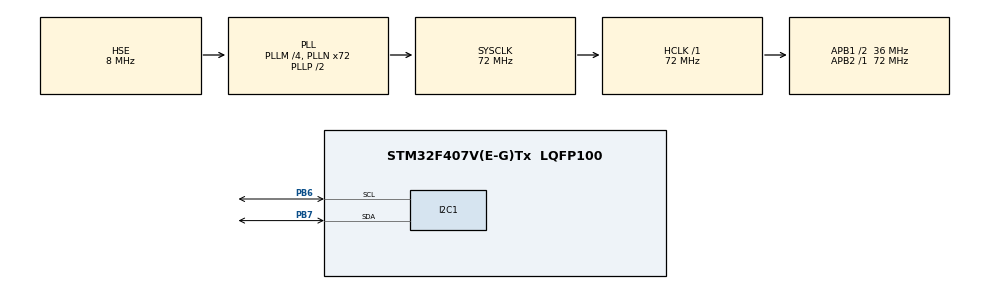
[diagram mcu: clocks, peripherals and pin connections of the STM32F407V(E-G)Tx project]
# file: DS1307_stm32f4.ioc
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Mcu.Family=STM32F4
Mcu.Name=STM32F407V(E-G)Tx
Mcu.Package=LQFP100
NVIC.PriorityGroup=NVIC_PRIORITYGROUP_4
PA13.Mode=Serial_Wire
PA13.Signal=SYS_JTMS-SWDIO
PA14.Mode=Serial_Wire
PA14.Signal=SYS_JTCK-SWCLK
PB6.Mode=I2C
PB6.Signal=I2C1_SCL
PB7.Mode=I2C
PB7.Signal=I2C1_SDA
PH0-OSC_IN.Mode=HSE-External-Oscillator
PH0-OSC_IN.Signal=RCC_OSC_IN
PH1-OSC_OUT.Mode=HSE-External-Oscillator
PH1-OSC_OUT.Signal=RCC_OSC_OUT
ProjectManager.HeapSize=0x200
ProjectManager.StackSize=0x400
ProjectManager.TargetToolchain=STM32CubeIDE
RCC.48MHZClocksFreq_Value=36000000
RCC.AHBFreq_Value=72000000
RCC.APB1CLKDivider=RCC_HCLK_DIV2
RCC.APB1Freq_Value=36000000
RCC.APB1TimFreq_Value=72000000
RCC.APB2Freq_Value=72000000
RCC.APB2TimFreq_Value=72000000
RCC.CortexFreq_Value=72000000
RCC.HCLKFreq_Value=72000000
RCC.HSE_VALUE=8000000
RCC.HSI_VALUE=16000000
RCC.LSE_VALUE=32768
RCC.PLLM=4
RCC.PLLN=72
RCC.PLLSourceVirtual=RCC_PLLSOURCE_HSE
RCC.SYSCLKFreq_VALUE=72000000
RCC.SYSCLKSource=RCC_SYSCLKSOURCE_PLLCLK
RCC.VCOOutputFreq_Value=144000000
board=custom

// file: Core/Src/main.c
/* USER CODE BEGIN Header */
/**
  ******************************************************************************
  * @file           : main.c
  * @brief          : Main program body
  ******************************************************************************
  * @attention
  *
  * Copyright (c) 2025 STMicroelectronics.
  * All rights reserved.
  *
  * This software is licensed under terms that can be found in the LICENSE file
  * in the root directory of this software component.
  * If no LICENSE file comes with this software, it is provided AS-IS.
  *
  ******************************************************************************
  */
/* USER CODE END Header */
#include "main.h"

/* USER CODE BEGIN Includes */
#include "main.h"
#include <stdio.h>

/* USER CODE END Includes */

/* USER CODE BEGIN PD */
// and the ds1307 for The contents of the time and calendar registers are in the binary-coded   decimal (BCD) format,
#define ds1307_write 0XD0
#define ds1307_read 0XD1
/* USER CODE END PD */

I2C_HandleTypeDef hi2c1;

/* USER CODE BEGIN PV */
// uint8_t adres;

typedef struct{

	uint8_t second;
	uint8_t minute;
	uint8_t hour;
	uint8_t day;
	uint8_t date;
	uint8_t month;
	uint16_t year;
}Ds1307_struct ;
Ds1307_struct ds_read;

/* USER CODE END PV */

void SystemClock_Config(void);
static void MX_GPIO_Init(void);
static void MX_I2C1_Init(void);

/* USER CODE BEGIN 0 */

uint8_t BCD_to_decimal(uint8_t bcd){

	return (uint8_t)(((bcd>>4)*10) + (bcd & 0x0f));
}													//Ds1307 de hafızada veriler bcd formatında saklanır bu yüzden dönüşüm şart,

uint8_t DEC_to_bcd(uint8_t dec){
	return (uint8_t)(((dec/10)<<4) |  (dec%10));
}

void Set_ds1307(uint8_t second,uint8_t minute,uint8_t hour,uint8_t day,uint8_t date,uint8_t month,uint8_t year){

	uint8_t timesdata[7]={0};
	timesdata[0]=DEC_to_bcd(second)  & 0x7F;
	timesdata[1]=DEC_to_bcd(minute);
	timesdata[2]=DEC_to_bcd(hour);
	timesdata[3]=DEC_to_bcd(day);
	timesdata[4]=DEC_to_bcd(date);
	timesdata[5]=DEC_to_bcd(month);
	timesdata[6]=DEC_to_bcd(year);

	HAL_I2C_Mem_Write(&hi2c1, ds1307_write, 0x00, I2C_MEMADD_SIZE_8BIT, timesdata, 7, HAL_MAX_DELAY);
}

void Get_ds1307(Ds1307_struct *datas){

	uint8_t buff[7]={0};

	HAL_I2C_Mem_Read(&hi2c1, ds1307_read, 0x00, I2C_MEMADD_SIZE_8BIT, buff, 7, HAL_MAX_DELAY);

    datas->second = BCD_to_decimal(buff[0] & 0x7F);
    datas->minute = BCD_to_decimal(buff[1]);
    datas->hour   = BCD_to_decimal(buff[2] & 0x3F);
    datas->day    = BCD_to_decimal(buff[3]);
    datas->date   = BCD_to_decimal(buff[4]);
    datas->month  = BCD_to_decimal(buff[5]);
    datas->year   = BCD_to_decimal(buff[6]) + 2000;

}

/* USER CODE END 0 */

int main(void)
{

  /* MCU Configuration--------------------------------------------------------*/

  /* Reset of all peripherals, Initializes the Flash interface and the Systick. */
  HAL_Init();

  /* Configure the system clock */
  SystemClock_Config();

  /* Initialize all configured peripherals */
  MX_GPIO_Init();
  MX_I2C1_Init();
  /* USER CODE BEGIN 2 */
  /*
  for(int i=0;i<255;i++){
	  if(HAL_I2C_IsDeviceReady(&hi2c1, i, 1, 100) == HAL_OK){
		  adres=i; // for find the device address and they are 208 and 209
	  }
  }
  */

  Set_ds1307(30, 30, 13, 6, 20, 12, 25); //You need to adjust it according to the current date.

  Get_ds1307(&ds_read);

  /* USER CODE END 2 */

  /* Infinite loop */
  while (1)
  {

    /* USER CODE BEGIN 3 */
	  Get_ds1307(&ds_read);
	  printf("%02d:%02d:%02d\r\n",
	         ds_read.hour,
	         ds_read.minute,
	         ds_read.second);
	  HAL_Delay(3000);
  }
  /* USER CODE END 3 */
}

void SystemClock_Config(void)
{
  RCC_OscInitTypeDef RCC_OscInitStruct = {0};
  RCC_ClkInitTypeDef RCC_ClkInitStruct = {0};

  /** Configure the main internal regulator output voltage
  */
  __HAL_RCC_PWR_CLK_ENABLE();
  __HAL_PWR_VOLTAGESCALING_CONFIG(PWR_REGULATOR_VOLTAGE_SCALE1);

  /** Initializes the RCC Oscillators according to the specified parameters
  * in the RCC_OscInitTypeDef structure.
  */
  RCC_OscInitStruct.OscillatorType = RCC_OSCILLATORTYPE_HSE;
  RCC_OscInitStruct.HSEState = RCC_HSE_ON;
  RCC_OscInitStruct.PLL.PLLState = RCC_PLL_ON;
  RCC_OscInitStruct.PLL.PLLSource = RCC_PLLSOURCE_HSE;
  RCC_OscInitStruct.PLL.PLLM = 4;
  RCC_OscInitStruct.PLL.PLLN = 72;
  RCC_OscInitStruct.PLL.PLLP = RCC_PLLP_DIV2;
  RCC_OscInitStruct.PLL.PLLQ = 4;
  if (HAL_RCC_OscConfig(&RCC_OscInitStruct) != HAL_OK)
  {
    Error_Handler();
  }

  /** Initializes the CPU, AHB and APB buses clocks
  */
  RCC_ClkInitStruct.ClockType = RCC_CLOCKTYPE_HCLK|RCC_CLOCKTYPE_SYSCLK
                              |RCC_CLOCKTYPE_PCLK1|RCC_CLOCKTYPE_PCLK2;
  RCC_ClkInitStruct.SYSCLKSource = RCC_SYSCLKSOURCE_PLLCLK;
  RCC_ClkInitStruct.AHBCLKDivider = RCC_SYSCLK_DIV1;
  RCC_ClkInitStruct.APB1CLKDivider = RCC_HCLK_DIV2;
  RCC_ClkInitStruct.APB2CLKDivider = RCC_HCLK_DIV1;

  if (HAL_RCC_ClockConfig(&RCC_ClkInitStruct, FLASH_LATENCY_2) != HAL_OK)
  {
    Error_Handler();
  }
}

static void MX_I2C1_Init(void)
{

  hi2c1.Instance = I2C1;
  hi2c1.Init.ClockSpeed = 100000;
  hi2c1.Init.DutyCycle = I2C_DUTYCYCLE_2;
  hi2c1.Init.OwnAddress1 = 0;
  hi2c1.Init.AddressingMode = I2C_ADDRESSINGMODE_7BIT;
  hi2c1.Init.DualAddressMode = I2C_DUALADDRESS_DISABLE;
  hi2c1.Init.OwnAddress2 = 0;
  hi2c1.Init.GeneralCallMode = I2C_GENERALCALL_DISABLE;
  hi2c1.Init.NoStretchMode = I2C_NOSTRETCH_DISABLE;
  if (HAL_I2C_Init(&hi2c1) != HAL_OK)
  {
    Error_Handler();
  }

}

static void MX_GPIO_Init(void)
{

  /* GPIO Ports Clock Enable */
  __HAL_RCC_GPIOH_CLK_ENABLE();
  __HAL_RCC_GPIOA_CLK_ENABLE();
  __HAL_RCC_GPIOB_CLK_ENABLE();

}

void Error_Handler(void)
{
  __disable_irq();
  while (1)
  {
  }
}
